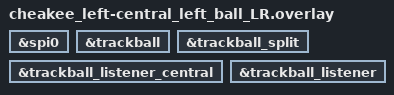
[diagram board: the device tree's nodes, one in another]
#include "cheakee.dtsi"

&spi0 {
    status = "okay";
};

&trackball {
    status = "okay";
};

&trackball_split {
    status = "okay";
};

&trackball_listener_central {
    status = "okay";
};

&trackball_listener {
    status = "okay";
};

